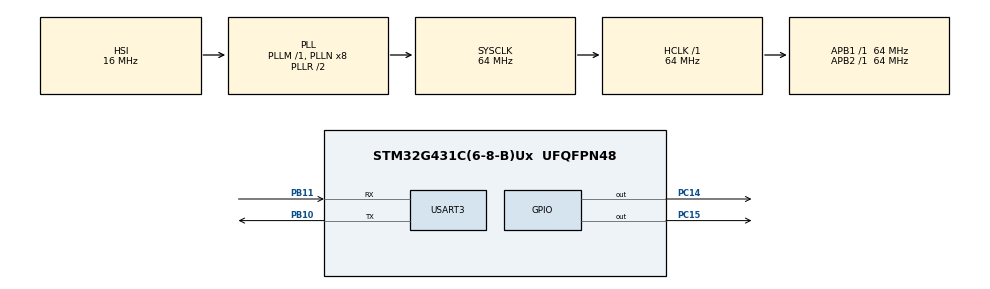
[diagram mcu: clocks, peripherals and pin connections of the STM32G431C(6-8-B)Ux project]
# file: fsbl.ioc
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Mcu.Family=STM32G4
Mcu.Name=STM32G431C(6-8-B)Ux
Mcu.Package=UFQFPN48
NVIC.PriorityGroup=NVIC_PRIORITYGROUP_4
PA13.Mode=Serial_Wire
PA13.Signal=SYS_JTMS-SWDIO
PA14.Mode=Serial_Wire
PA14.Signal=SYS_JTCK-SWCLK
PB10.Mode=Asynchronous
PB10.Signal=USART3_TX
PB11.Mode=Asynchronous
PB11.Signal=USART3_RX
PC14-OSC32_IN.Signal=GPIO_Output
PC15-OSC32_OUT.PinState=GPIO_PIN_SET
PC15-OSC32_OUT.Signal=GPIO_Output
ProjectManager.HeapSize=0x200
ProjectManager.StackSize=0x400
ProjectManager.TargetToolchain=STM32CubeIDE
RCC.ADC12Freq_Value=64000000
RCC.AHBFreq_Value=64000000
RCC.APB1Freq_Value=64000000
RCC.APB1TimFreq_Value=64000000
RCC.APB2Freq_Value=64000000
RCC.APB2TimFreq_Value=64000000
RCC.CortexFreq_Value=64000000
RCC.EXTERNAL_CLOCK_VALUE=12288000
RCC.HCLKFreq_Value=64000000
RCC.HSE_VALUE=8000000
RCC.HSI48_VALUE=48000000
RCC.HSI_VALUE=16000000
RCC.LSE_VALUE=32768
RCC.SYSCLKFreq_VALUE=64000000
RCC.SYSCLKSource=RCC_SYSCLKSOURCE_PLLCLK
RCC.USBFreq_Value=64000000
RCC.VCOOutputFreq_Value=128000000
USART3.VirtualMode-Asynchronous=VM_ASYNC
VP_SYS_VS_DBSignals.Mode=DisableDeadBatterySignals
board=custom

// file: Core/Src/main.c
/* USER CODE BEGIN Header */
/**
  ******************************************************************************
  * @file           : main.c
  * @brief          : Main program body
  ******************************************************************************
  * @attention
  *
  * Copyright (c) 2025 STMicroelectronics.
  * All rights reserved.
  *
  * This software is licensed under terms that can be found in the LICENSE file
  * in the root directory of this software component.
  * If no LICENSE file comes with this software, it is provided AS-IS.
  *
  ******************************************************************************
  */
/* USER CODE END Header */
#include "main.h"

void SystemClock_Config(void);
static void MX_GPIO_Init(void);
static void MX_USART3_UART_Init(void);

int main(void)
{

  /* MCU Configuration--------------------------------------------------------*/

  /* Reset of all peripherals, Initializes the Flash interface and the Systick. */
  HAL_Init();

  /* Configure the system clock */
  SystemClock_Config();

  /* Initialize all configured peripherals */
  MX_GPIO_Init();
  MX_USART3_UART_Init();
  /* USER CODE BEGIN 2 */
  extern int main_task();
  main_task();
  /* USER CODE END 2 */

  /* Infinite loop */
  while (1)
  {

  }
}

void SystemClock_Config(void)
{
  RCC_OscInitTypeDef RCC_OscInitStruct = {0};
  RCC_ClkInitTypeDef RCC_ClkInitStruct = {0};

  /** Configure the main internal regulator output voltage
  */
  HAL_PWREx_ControlVoltageScaling(PWR_REGULATOR_VOLTAGE_SCALE1);

  /** Initializes the RCC Oscillators according to the specified parameters
  * in the RCC_OscInitTypeDef structure.
  */
  RCC_OscInitStruct.OscillatorType = RCC_OSCILLATORTYPE_HSI;
  RCC_OscInitStruct.HSIState = RCC_HSI_ON;
  RCC_OscInitStruct.HSICalibrationValue = RCC_HSICALIBRATION_DEFAULT;
  RCC_OscInitStruct.PLL.PLLState = RCC_PLL_ON;
  RCC_OscInitStruct.PLL.PLLSource = RCC_PLLSOURCE_HSI;
  RCC_OscInitStruct.PLL.PLLM = RCC_PLLM_DIV1;
  RCC_OscInitStruct.PLL.PLLN = 8;
  RCC_OscInitStruct.PLL.PLLP = RCC_PLLP_DIV2;
  RCC_OscInitStruct.PLL.PLLQ = RCC_PLLQ_DIV2;
  RCC_OscInitStruct.PLL.PLLR = RCC_PLLR_DIV2;
  if (HAL_RCC_OscConfig(&RCC_OscInitStruct) != HAL_OK)
  {
    Error_Handler();
  }

  /** Initializes the CPU, AHB and APB buses clocks
  */
  RCC_ClkInitStruct.ClockType = RCC_CLOCKTYPE_HCLK|RCC_CLOCKTYPE_SYSCLK
                              |RCC_CLOCKTYPE_PCLK1|RCC_CLOCKTYPE_PCLK2;
  RCC_ClkInitStruct.SYSCLKSource = RCC_SYSCLKSOURCE_PLLCLK;
  RCC_ClkInitStruct.AHBCLKDivider = RCC_SYSCLK_DIV1;
  RCC_ClkInitStruct.APB1CLKDivider = RCC_HCLK_DIV1;
  RCC_ClkInitStruct.APB2CLKDivider = RCC_HCLK_DIV1;

  if (HAL_RCC_ClockConfig(&RCC_ClkInitStruct, FLASH_LATENCY_2) != HAL_OK)
  {
    Error_Handler();
  }
}

static void MX_USART3_UART_Init(void)
{

  LL_USART_InitTypeDef USART_InitStruct = {0};

  LL_GPIO_InitTypeDef GPIO_InitStruct = {0};
  RCC_PeriphCLKInitTypeDef PeriphClkInit = {0};

  /** Initializes the peripherals clocks
  */
  PeriphClkInit.PeriphClockSelection = RCC_PERIPHCLK_USART3;
  PeriphClkInit.Usart3ClockSelection = RCC_USART3CLKSOURCE_PCLK1;
  if (HAL_RCCEx_PeriphCLKConfig(&PeriphClkInit) != HAL_OK)
  {
    Error_Handler();
  }

  /* Peripheral clock enable */
  LL_APB1_GRP1_EnableClock(LL_APB1_GRP1_PERIPH_USART3);

  LL_AHB2_GRP1_EnableClock(LL_AHB2_GRP1_PERIPH_GPIOB);
  /**USART3 GPIO Configuration
  PB10   ------> USART3_TX
  PB11   ------> USART3_RX
  */
  GPIO_InitStruct.Pin = LL_GPIO_PIN_10;
  GPIO_InitStruct.Mode = LL_GPIO_MODE_ALTERNATE;
  GPIO_InitStruct.Speed = LL_GPIO_SPEED_FREQ_LOW;
  GPIO_InitStruct.OutputType = LL_GPIO_OUTPUT_PUSHPULL;
  GPIO_InitStruct.Pull = LL_GPIO_PULL_NO;
  GPIO_InitStruct.Alternate = LL_GPIO_AF_7;
  LL_GPIO_Init(GPIOB, &GPIO_InitStruct);

  GPIO_InitStruct.Pin = LL_GPIO_PIN_11;
  GPIO_InitStruct.Mode = LL_GPIO_MODE_ALTERNATE;
  GPIO_InitStruct.Speed = LL_GPIO_SPEED_FREQ_LOW;
  GPIO_InitStruct.OutputType = LL_GPIO_OUTPUT_PUSHPULL;
  GPIO_InitStruct.Pull = LL_GPIO_PULL_NO;
  GPIO_InitStruct.Alternate = LL_GPIO_AF_7;
  LL_GPIO_Init(GPIOB, &GPIO_InitStruct);

  USART_InitStruct.PrescalerValue = LL_USART_PRESCALER_DIV1;
  USART_InitStruct.BaudRate = 115200;
  USART_InitStruct.DataWidth = LL_USART_DATAWIDTH_8B;
  USART_InitStruct.StopBits = LL_USART_STOPBITS_1;
  USART_InitStruct.Parity = LL_USART_PARITY_NONE;
  USART_InitStruct.TransferDirection = LL_USART_DIRECTION_TX_RX;
  USART_InitStruct.HardwareFlowControl = LL_USART_HWCONTROL_NONE;
  USART_InitStruct.OverSampling = LL_USART_OVERSAMPLING_16;
  LL_USART_Init(USART3, &USART_InitStruct);
  LL_USART_SetTXFIFOThreshold(USART3, LL_USART_FIFOTHRESHOLD_1_8);
  LL_USART_SetRXFIFOThreshold(USART3, LL_USART_FIFOTHRESHOLD_1_8);
  LL_USART_DisableFIFO(USART3);
  LL_USART_ConfigAsyncMode(USART3);

  LL_USART_Enable(USART3);

  /* Polling USART3 initialisation */
  while((!(LL_USART_IsActiveFlag_TEACK(USART3))) || (!(LL_USART_IsActiveFlag_REACK(USART3))))
  {
  }

}

static void MX_GPIO_Init(void)
{
  LL_GPIO_InitTypeDef GPIO_InitStruct = {0};

  /* GPIO Ports Clock Enable */
  LL_AHB2_GRP1_EnableClock(LL_AHB2_GRP1_PERIPH_GPIOC);
  LL_AHB2_GRP1_EnableClock(LL_AHB2_GRP1_PERIPH_GPIOB);
  LL_AHB2_GRP1_EnableClock(LL_AHB2_GRP1_PERIPH_GPIOA);

  /**/
  LL_GPIO_ResetOutputPin(GPIOC, LL_GPIO_PIN_14);

  /**/
  LL_GPIO_SetOutputPin(GPIOC, LL_GPIO_PIN_15);

  /**/
  GPIO_InitStruct.Pin = LL_GPIO_PIN_14;
  GPIO_InitStruct.Mode = LL_GPIO_MODE_OUTPUT;
  GPIO_InitStruct.Speed = LL_GPIO_SPEED_FREQ_LOW;
  GPIO_InitStruct.OutputType = LL_GPIO_OUTPUT_PUSHPULL;
  GPIO_InitStruct.Pull = LL_GPIO_PULL_NO;
  LL_GPIO_Init(GPIOC, &GPIO_InitStruct);

  /**/
  GPIO_InitStruct.Pin = LL_GPIO_PIN_15;
  GPIO_InitStruct.Mode = LL_GPIO_MODE_OUTPUT;
  GPIO_InitStruct.Speed = LL_GPIO_SPEED_FREQ_LOW;
  GPIO_InitStruct.OutputType = LL_GPIO_OUTPUT_PUSHPULL;
  GPIO_InitStruct.Pull = LL_GPIO_PULL_NO;
  LL_GPIO_Init(GPIOC, &GPIO_InitStruct);

}

void Error_Handler(void)
{
  __disable_irq();
  while (1)
  {
  }
}
